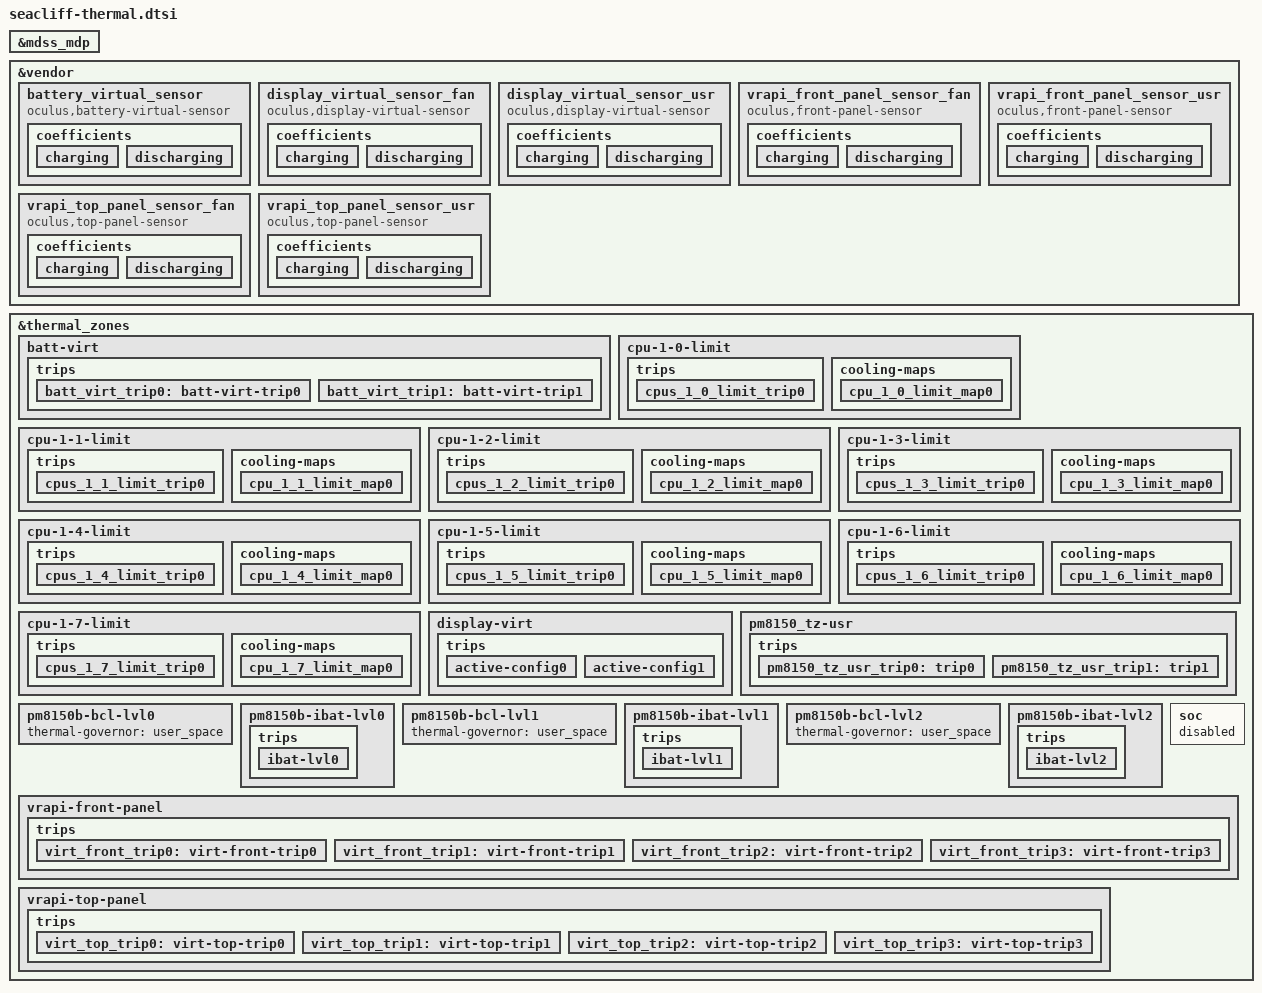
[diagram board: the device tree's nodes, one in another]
&mdss_mdp {
	#cooling-cells = <2>;
};

&vendor {
	battery_virtual_sensor: battery_virtual_sensor {
		compatible = "oculus,battery-virtual-sensor";
		status = "ok";
		#thermal-sensor-cells = <0>;

		pcm-thermal-zone = "battery";
		pcm-thermal-zone-scaling-factor = <1>;

		thermal-zones = "battery";
		thermal-zone-scaling-factors = <1>;

		max-differential = <10000>;
		internal-polling-delay = <1000>;

		coefficients {
			charging {
				tz-coefficients = <5061>;
				tz-slope-coefficients = <500>;
				intercept = <14511>;
			};
			discharging {
				tz-coefficients = <5061>;
				tz-slope-coefficients = <500>;
				intercept = <14511>;
			};
		};
	};

	display_virtual_sensor_fan: display_virtual_sensor_fan {
		compatible = "oculus,display-virtual-sensor";
		status = "ok";
		#thermal-sensor-cells = <0>;

		io-channels = <&pm8150b_vadc ADC_AMUX_THM4_PU2>;
		io-channel-names = "pcb1_therm";

		thermal-zones = "rfpa-usr", "cpu-1-4-usr", "npu-usr",
				"smb-usr", "pogo-charger";

		internal-polling-delay = <1000>;

		coefficients {
			charging {
				tz-coefficients = <633 255 304 (-376) 2302>;
				tz-slope-coefficients = <500 (-85) (-8500) (-5500) 1500>;
				io-coefficients = <775>;
				io-slope-coefficients = <(-15500)>;
				intercept = <19771>;
			};
			discharging {
				tz-coefficients = <633 255 304 (-376) 2302>;
				tz-slope-coefficients = <500 (-85) (-8500) (-5500) 1500>;
				io-coefficients = <775>;
				io-slope-coefficients = <(-15500)>;
				intercept = <19771>;
			};
		};
	};

	display_virtual_sensor_usr: display_virtual_sensor_usr {
		compatible = "oculus,display-virtual-sensor";
		status = "ok";
		#thermal-sensor-cells = <0>;

		io-channels = <&pm8150b_vadc ADC_AMUX_THM4_PU2>;
		io-channel-names = "pcb1_therm";

		thermal-zones = "rfpa-usr", "cpu-1-4-usr", "npu-usr",
				"smb-usr", "pogo-charger";

		internal-polling-delay = <1000>;

		coefficients {
			charging {
				tz-coefficients = <633 255 304 (-376) 2302>;
				tz-slope-coefficients = <500 (-85) (-8500) (-5500) 1500>;
				io-coefficients = <775>;
				io-slope-coefficients = <(-15500)>;
				intercept = <19771>;
			};
			discharging {
				tz-coefficients = <633 255 304 (-376) 2302>;
				tz-slope-coefficients = <500 (-85) (-8500) (-5500) 1500>;
				io-coefficients = <775>;
				io-slope-coefficients = <(-15500)>;
				intercept = <19771>;
			};
		};
	};

	vrapi_front_panel_sensor_fan: vrapi_front_panel_sensor_fan {
		compatible = "oculus,front-panel-sensor";
		status = "ok";
		#thermal-sensor-cells = <0>;

		io-channels = <&pm8150b_vadc ADC_AMUX_THM4_PU2>;
		io-channel-names = "pcb1_therm";

		thermal-zones = "rfpa-usr", "cpu-1-4-usr", "npu-usr",
				"smb-usr", "ddr-usr", "pogo-charger";

		internal-polling-delay = <1000>;

		coefficients {
			charging {
				tz-coefficients = <935 633 760 (-566) 612 2527>;
				tz-slope-coefficients = <500 (-85) (-8500) (-5500) 500 1500>;
				io-coefficients = <1077>;
				io-slope-coefficients = <(-15500)>;
				intercept = <8825>;
			};
			discharging {
				tz-coefficients = <935 633 760 (-566) 612 2527>;
				tz-slope-coefficients = <500 (-85) (-8500) (-5500) 500 1500>;
				io-coefficients = <1077>;
				io-slope-coefficients = <(-15500)>;
				intercept = <8825>;
			};
		};
	};

	vrapi_front_panel_sensor_usr: vrapi_front_panel_sensor_usr {
		compatible = "oculus,front-panel-sensor";
		status = "ok";
		#thermal-sensor-cells = <0>;

		io-channels = <&pm8150b_vadc ADC_AMUX_THM4_PU2>;
		io-channel-names = "pcb1_therm";

		thermal-zones = "rfpa-usr", "cpu-1-4-usr", "npu-usr",
				"smb-usr", "ddr-usr", "pogo-charger";

		internal-polling-delay = <1000>;

		coefficients {
			charging {
				tz-coefficients = <935 633 760 (-566) 612 2527>;
				tz-slope-coefficients = <500 (-85) (-8500) (-5500) 500 1500>;
				io-coefficients = <1077>;
				io-slope-coefficients = <(-15500)>;
				intercept = <8825>;
			};
			discharging {
				tz-coefficients = <935 633 760 (-566) 612 2527>;
				tz-slope-coefficients = <500 (-85) (-8500) (-5500) 500 1500>;
				io-coefficients = <1077>;
				io-slope-coefficients = <(-15500)>;
				intercept = <8825>;
			};
		};
	};

	vrapi_top_panel_sensor_fan: vrapi_top_panel_sensor_fan {
		compatible = "oculus,top-panel-sensor";
		status = "ok";
		#thermal-sensor-cells = <0>;

		io-channels = <&pm8150b_vadc ADC_AMUX_THM4_PU2>;
		io-channel-names = "pcb1_therm";

		thermal-zones = "rfpa-usr", "cpu-1-4-usr", "npu-usr",
				"smb-usr", "ddr-usr", "pogo-charger";

		internal-polling-delay = <1000>;

		coefficients {
			charging {
				tz-coefficients = <978 631 810 (-591) 628 2722>;
				tz-slope-coefficients = <500 (-85) (-8500) (-5500) 500 500 1500>;
				io-coefficients = <1174>;
				io-slope-coefficients = <(-15500)>;
				intercept = <6211>;
			};
			discharging {
				tz-coefficients = <978 631 810 (-591) 628 2722>;
				tz-slope-coefficients = <500 (-85) (-8500) (-5500) 500 500 1500>;
				io-coefficients = <1174>;
				io-slope-coefficients = <(-15500)>;
				intercept = <6211>;
			};
		};
	};

	vrapi_top_panel_sensor_usr: vrapi_top_panel_sensor_usr {
		compatible = "oculus,top-panel-sensor";
		status = "ok";
		#thermal-sensor-cells = <0>;

		io-channels = <&pm8150b_vadc ADC_AMUX_THM4_PU2>;
		io-channel-names = "pcb1_therm";

		thermal-zones = "rfpa-usr", "cpu-1-4-usr", "npu-usr",
				"smb-usr", "ddr-usr", "pogo-charger";

		internal-polling-delay = <1000>;

		coefficients {
			charging {
				tz-coefficients = <978 631 810 (-591) 628 2722>;
				tz-slope-coefficients = <500 (-85) (-8500) (-5500) 500 500 1500>;
				io-coefficients = <1174>;
				io-slope-coefficients = <(-15500)>;
				intercept = <6211>;
			};
			discharging {
				tz-coefficients = <978 631 810 (-591) 628 2722>;
				tz-slope-coefficients = <500 (-85) (-8500) (-5500) 500 500 1500>;
				io-coefficients = <1174>;
				io-slope-coefficients = <(-15500)>;
				intercept = <6211>;
			};
		};
	};
};


&thermal_zones {
	batt-virt {
		polling-delay-passive = <0>;
		polling-delay = <0>;
		thermal-governor = "user_space";
		thermal-sensors = <&battery_virtual_sensor>;
		wake-capable-sensor;
		trips {
			batt_virt_trip0: batt-virt-trip0 {
				temperature = <58500>;
				hysteresis = <2000>;
				type = "passive";
			};
			batt_virt_trip1: batt-virt-trip1 {
				temperature = <60000>;
				hysteresis = <1000>;
				type = "passive";
			};
		};
	};

	cpu-1-0-limit {
		polling-delay-passive = <0>;
		polling-delay = <0>;
		thermal-sensors = <&tsens0 7>;
		thermal-governor = "single_step";
		wake-capable-sensor;
		trips {
			cpus_1_0_limit_trip0: cpus_1_0_limit_trip0 {
				temperature = <90000>;
				hysteresis = <5000>;
				type = "passive";
			};
		};
		cooling-maps {
			cpu_1_0_limit_map0: cpu_1_0_limit_map0 {
				trip = <&cpus_1_0_limit_trip0>;
				cooling-device = <&CPU4 0 10>;
			};
		};
	};

	cpu-1-1-limit {
		polling-delay-passive = <0>;
		polling-delay = <0>;
		thermal-sensors = <&tsens0 8>;
		thermal-governor = "single_step";
		wake-capable-sensor;
		trips {
			cpus_1_1_limit_trip0: cpus_1_1_limit_trip0 {
				temperature = <90000>;
				hysteresis = <5000>;
				type = "passive";
			};
		};
		cooling-maps {
			cpu_1_1_limit_map0: cpu_1_1_limit_map0 {
				trip = <&cpus_1_1_limit_trip0>;
				cooling-device = <&CPU4 0 10>;
			};
		};
	};

	cpu-1-2-limit {
		polling-delay-passive = <0>;
		polling-delay = <0>;
		thermal-sensors = <&tsens0 9>;
		thermal-governor = "single_step";
		wake-capable-sensor;
		trips {
			cpus_1_2_limit_trip0: cpus_1_2_limit_trip0 {
				temperature = <90000>;
				hysteresis = <5000>;
				type = "passive";
			};
		};
		cooling-maps {
			cpu_1_2_limit_map0: cpu_1_2_limit_map0 {
				trip = <&cpus_1_2_limit_trip0>;
				cooling-device = <&CPU4 0 10>;
			};
		};
	};

	cpu-1-3-limit {
		polling-delay-passive = <0>;
		polling-delay = <0>;
		thermal-sensors = <&tsens0 10>;
		thermal-governor = "single_step";
		wake-capable-sensor;
		trips {
			cpus_1_3_limit_trip0: cpus_1_3_limit_trip0 {
				temperature = <90000>;
				hysteresis = <5000>;
				type = "passive";
			};
		};
		cooling-maps {
			cpu_1_3_limit_map0: cpu_1_3_limit_map0 {
				trip = <&cpus_1_3_limit_trip0>;
				cooling-device = <&CPU7 0 17>;
			};
		};
	};

	cpu-1-4-limit {
		polling-delay-passive = <0>;
		polling-delay = <0>;
		thermal-sensors = <&tsens0 11>;
		thermal-governor = "single_step";
		wake-capable-sensor;
		trips {
			cpus_1_4_limit_trip0: cpus_1_4_limit_trip0 {
				temperature = <90000>;
				hysteresis = <5000>;
				type = "passive";
			};
		};
		cooling-maps {
			cpu_1_4_limit_map0: cpu_1_4_limit_map0 {
				trip = <&cpus_1_4_limit_trip0>;
				cooling-device = <&CPU4 0 10>;
			};
		};
	};

	cpu-1-5-limit {
		polling-delay-passive = <0>;
		polling-delay = <0>;
		thermal-sensors = <&tsens0 12>;
		thermal-governor = "single_step";
		wake-capable-sensor;
		trips {
			cpus_1_5_limit_trip0: cpus_1_5_limit_trip0 {
				temperature = <90000>;
				hysteresis = <5000>;
				type = "passive";
			};
		};
		cooling-maps {
			cpu_1_5_limit_map0: cpu_1_5_limit_map0 {
				trip = <&cpus_1_5_limit_trip0>;
				cooling-device = <&CPU4 0 10>;
			};
		};
	};

	cpu-1-6-limit {
		polling-delay-passive = <0>;
		polling-delay = <0>;
		thermal-sensors = <&tsens0 13>;
		thermal-governor = "single_step";
		wake-capable-sensor;
		trips {
			cpus_1_6_limit_trip0: cpus_1_6_limit_trip0 {
				temperature = <90000>;
				hysteresis = <5000>;
				type = "passive";
			};
		};
		cooling-maps {
			cpu_1_6_limit_map0: cpu_1_6_limit_map0 {
				trip = <&cpus_1_6_limit_trip0>;
				cooling-device = <&CPU4 0 10>;
			};
		};
	};

	cpu-1-7-limit {
		polling-delay-passive = <0>;
		polling-delay = <0>;
		thermal-sensors = <&tsens0 14>;
		thermal-governor = "single_step";
		wake-capable-sensor;
		trips {
			cpus_1_7_limit_trip0: cpus_1_7_limit_trip0 {
				temperature = <90000>;
				hysteresis = <5000>;
				type = "passive";
			};
		};
		cooling-maps {
			cpu_1_7_limit_map0: cpu_1_7_limit_map0 {
				trip = <&cpus_1_7_limit_trip0>;
				cooling-device = <&CPU7 0 17>;
			};
		};
	};

	display-virt {
		polling-delay-passive = <0>;
		polling-delay = <0>;
		thermal-governor = "user_space";
		thermal-sensors = <&display_virtual_sensor_usr>;
		wake-capable-sensor;
		trips {
			active-config0 {
				temperature = <125000>;
				hysteresis = <1000>;
				type = "passive";
			};
			active-config1 {
				temperature = <125000>;
				hysteresis = <1000>;
				type = "passive";
			};
		};
	};

	pm8150_tz-usr {
		polling-delay-passive = <100>;
		polling-delay = <0>;
		thermal-governor = "user_space";
		thermal-sensors = <&pm8150_tz>;
		wake-capable-sensor;
		trips {
			pm8150_tz_usr_trip0: trip0 {
				temperature = <85000>;
				hysteresis = <5000>;
				type = "passive";
			};
			pm8150_tz_usr_trip1: trip1 {
				temperature = <120000>;
				hysteresis = <5000>;
				type = "passive";
			};
		};
	};

	pm8150b-bcl-lvl0 {
		thermal-governor = "user_space";
	};

	pm8150b-ibat-lvl0 {
			trips {
			ibat-lvl0 {
				/* this is actually current in mA */
				temperature = <6500>;
				hysteresis = <200>;
			};
		};
	};

	pm8150b-bcl-lvl1 {
		thermal-governor = "user_space";
	};

	pm8150b-ibat-lvl1 {
		trips {
			ibat-lvl1 {
				/* this is actually current in mA */
				temperature = <7000>;
				hysteresis = <200>;
			};
		};
	};

	pm8150b-bcl-lvl2 {
		thermal-governor = "user_space";
	};

	pm8150b-ibat-lvl2 {
		trips {
			ibat-lvl2 {
				/* this is actually current in mA */
				temperature = <7500>;
				hysteresis = <200>;
			};
		};
	};

	soc {
		status = "disabled";
	};

	vrapi-front-panel {
		polling-delay-passive = <0>;
		polling-delay = <0>;
		thermal-governor = "user_space";
		thermal-sensors = <&vrapi_front_panel_sensor_usr>;
		wake-capable-sensor;
		trips {
			virt_front_trip0: virt-front-trip0 {
				temperature = <85000>;
				hysteresis = <1000>;
				type = "passive";
			};
			virt_front_trip1: virt-front-trip1 {
				temperature = <95000>;
				hysteresis = <1000>;
				type = "passive";
			};
			virt_front_trip2: virt-front-trip2 {
				temperature = <115000>;
				hysteresis = <1000>;
				type = "passive";
			};
			virt_front_trip3: virt-front-trip3 {
				temperature = <125000>;
				hysteresis = <1000>;
				type = "passive";
			};
		};
	};

	vrapi-top-panel {
		polling-delay-passive = <0>;
		polling-delay = <0>;
		thermal-governor = "user_space";
		thermal-sensors = <&vrapi_top_panel_sensor_usr>;
		wake-capable-sensor;
		trips {
			virt_top_trip0: virt-top-trip0 {
				temperature = <85000>;
				hysteresis = <1000>;
				type = "passive";
			};
			virt_top_trip1: virt-top-trip1 {
				temperature = <95000>;
				hysteresis = <1000>;
				type = "passive";
			};
			virt_top_trip2: virt-top-trip2 {
				temperature = <115000>;
				hysteresis = <1000>;
				type = "passive";
			};
			virt_top_trip3: virt-top-trip3 {
				temperature = <125000>;
				hysteresis = <1000>;
				type = "passive";
			};
		};
	};
};
